# MKW21Z4 register map
Vendor: Freescale Semiconductor, Inc.; Series: Kinetis_W; File version: 1.6
CPU: CM0PLUS r0p0, little endian, no MPU, no FPU, VTOR, 2 interrupt priority bits
Registers are 16-bit, read-write, no defined reset value unless marked. A register's access mark holds for its fields unless they carry their own. Offsets are from the block's base; [hi:lo] are bit positions; {n}, {i} and the like mark numbered series.

## XCVR_ZBDEMOD_REGS — XCVR_ZBDEMOD
Base 0x4005C480
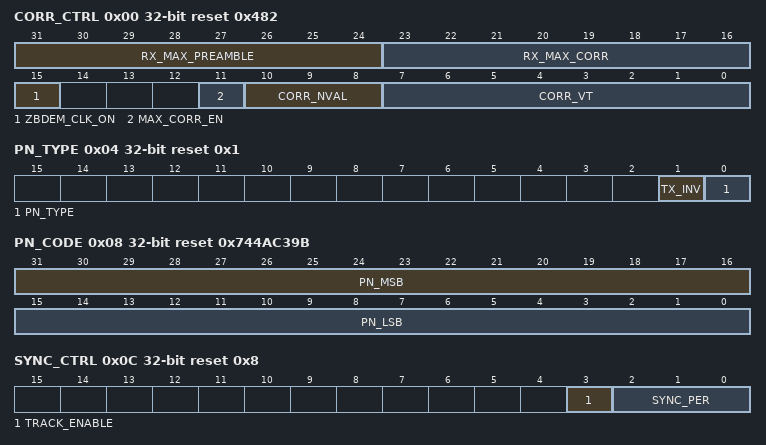
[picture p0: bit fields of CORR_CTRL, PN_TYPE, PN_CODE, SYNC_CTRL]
0x00 CORR_CTRL 32-bit reset 0x482 (reset mask 0xFFFF) — 802.15.4 DEMOD CORRELLATOR CONTROL
  [31:24] RX_MAX_PREAMBLE ro
  [23:16] RX_MAX_CORR ro
  [15] ZBDEM_CLK_ON — Force 802.15.4 Demodulator Clock On
    0=Normal Operation; 1=Force 802.15.4 Demodulator Clock On (debug purposes only)
  [11] MAX_CORR_EN
  [10:8] CORR_NVAL
  [7:0] CORR_VT
0x04 PN_TYPE 32-bit reset 0x1 — 802.15.4 DEMOD PN TYPE
  [1] TX_INV, [0] PN_TYPE
0x08 PN_CODE 32-bit reset 0x744AC39B — 802.15.4 DEMOD PN CODE
  [31:16] PN_MSB, [15:0] PN_LSB
0x0C SYNC_CTRL 32-bit reset 0x8 — 802.15.4 DEMOD SYMBOL SYNC CONTROL
  [3] TRACK_ENABLE
    0=symbol timing synchronization tracking disabled in Rx frontend; 1=symbol timing synchronization tracking enabled in Rx frontend (default)
  [2:0] SYNC_PER — Symbol Sync Tracking Period
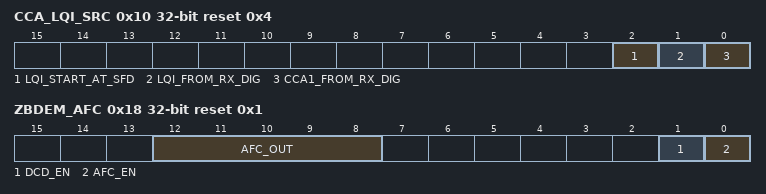
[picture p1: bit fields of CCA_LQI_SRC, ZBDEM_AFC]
0x10 CCA_LQI_SRC 32-bit reset 0x4 — 802.15.4 CCA/LQI SOURCE
  [2] LQI_START_AT_SFD — Select Start Point for LQI Computation
    0=Start LQI computation at Preamble Detection (similar to previous Freescale 802.15.4 products); 1=Start LQI computation at SFD (Start of Frame Delimiter) Detection
  [1] LQI_FROM_RX_DIG — Selects the Source of LQI (Link Quality Indicator) Information Provided to the 802.15.4 Link Layer
    0=Use the LQI information computed internally in the 802.15.4 Demod; 1=Use the LQI information computed by the RX Digital
  [0] CCA1_FROM_RX_DIG — Selects the Source of CCA1 (Clear Channel Assessment Mode 1) Information Provided to the 802.15.4 Link Layer
    0=Use the CCA1 information computed internally in the 802.15.4 Demod; 1=Use the CCA1 information computed by the RX Digital
0x14 FAD_THR 32-bit reset 0x82 — FAD CORRELATOR THRESHOLD
  [7:0] FAD_THR
0x18 ZBDEM_AFC 32-bit reset 0x1 (reset mask 0xFFFFE0FF) — 802.15.4 AFC STATUS
  [12:8] AFC_OUT ro
  [1] DCD_EN
    0=NCD Mode (default); 1=DCD Mode
  [0] AFC_EN
    0=AFC is disabled; 1=AFC is enabled

## XCVR_PKT_RAM
Base 0x4005C700
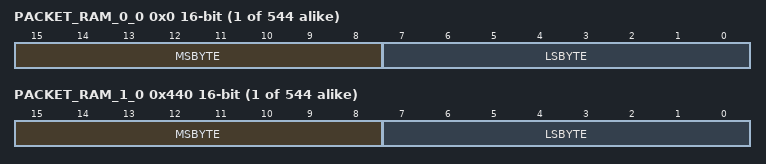
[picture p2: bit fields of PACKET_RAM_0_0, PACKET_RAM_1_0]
{0x0+2i} PACKET_RAM_0_{i} (i=0..543) — Shared Packet RAM for multiple Link Layer usage.
  [15:8] MSBYTE, [7:0] LSBYTE
{0x440+2i} PACKET_RAM_1_{i} (i=0..543) — Shared Packet RAM for multiple Link Layer usage.
  [15:8] MSBYTE, [7:0] LSBYTE

## CMT — Carrier Modulator Transmitter
Base 0x40062000; register names take the prefix CMT_
0x00 CGH1 8-bit — CMT Carrier Generator High Data Register 1
  [7:0] PH — Primary Carrier High Time Data Value
0x01 CGL1 8-bit — CMT Carrier Generator Low Data Register 1
  [7:0] PL — Primary Carrier Low Time Data Value
0x02 CGH2 8-bit — CMT Carrier Generator High Data Register 2
  [7:0] SH — Secondary Carrier High Time Data Value
0x03 CGL2 8-bit — CMT Carrier Generator Low Data Register 2
  [7:0] SL — Secondary Carrier Low Time Data Value
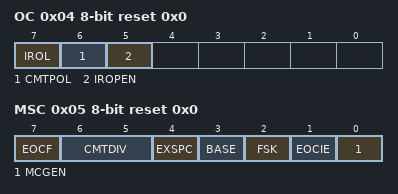
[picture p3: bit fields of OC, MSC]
0x04 OC 8-bit reset 0x0 — CMT Output Control Register
  [7] IROL — IRO Latch Control
  [6] CMTPOL — CMT Output Polarity
    0=The IRO signal is active-low; 1=The IRO signal is active-high
  [5] IROPEN — IRO Pin Enable
    0=The IRO signal is disabled; 1=The IRO signal is enabled as output
0x05 MSC 8-bit reset 0x0 — CMT Modulator Status and Control Register
  [7] EOCF ro — End Of Cycle Status Flag
    0=End of modulation cycle has not occured since the flag last cleared; 1=End of modulator cycle has occurred
  [6:5] CMTDIV — CMT Clock Divide Prescaler
    0=IF * 1; 1=IF * 2; 2=IF * 4; 3=IF * 8
  [4] EXSPC — Extended Space Enable
    0=Extended space is disabled; 1=Extended space is enabled
  [3] BASE — Baseband Enable
    0=Baseband mode is disabled; 1=Baseband mode is enabled
  [2] FSK — FSK Mode Select
    0=The CMT operates in Time or Baseband mode; 1=The CMT operates in FSK mode
  [1] EOCIE — End of Cycle Interrupt Enable
    0=CPU interrupt is disabled; 1=CPU interrupt is enabled
  [0] MCGEN — Modulator and Carrier Generator Enable
    0=Modulator and carrier generator disabled; 1=Modulator and carrier generator enabled
0x06 CMD1 8-bit — CMT Modulator Data Register Mark High
  [7:0] MB — MB[15:8]
0x07 CMD2 8-bit — CMT Modulator Data Register Mark Low
  [7:0] MB — MB[7:0]
0x08 CMD3 8-bit — CMT Modulator Data Register Space High
  [7:0] SB — SB[15:8]
0x09 CMD4 8-bit — CMT Modulator Data Register Space Low
  [7:0] SB — SB[7:0]
0x0A PPS 8-bit reset 0x0 — CMT Primary Prescaler Register
  [3:0] PPSDIV — Primary Prescaler Divider
    {v}=Bus clock * {v+1} (v=0..15)
0x0B DMA 8-bit reset 0x0 — CMT Direct Memory Access Register
  [0] DMA — DMA Enable
    0=DMA transfer request and done are disabled; 1=DMA transfer request and done are enabled
